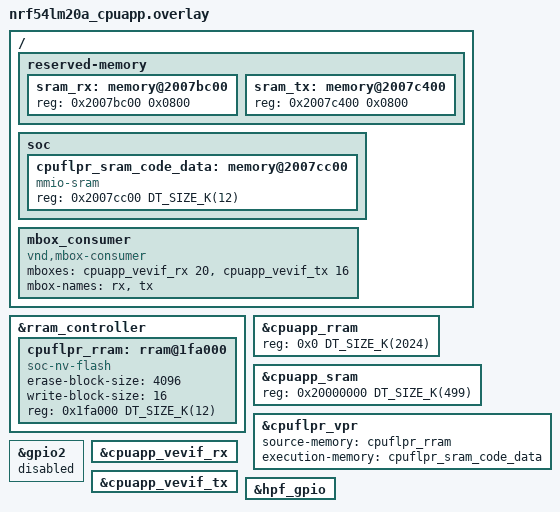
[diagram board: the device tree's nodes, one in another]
/*
 * Copyright (c) 2025 Nordic Semiconductor ASA
 *
 * SPDX-License-Identifier: LicenseRef-Nordic-5-Clause
 */

#include "../../hpf-gpio-app.overlay"

/ {
	reserved-memory {
		#address-cells = <1>;
		#size-cells = <1>;

		sram_rx: memory@2007bc00 {
			reg = <0x2007bc00 0x0800>;
		};

		sram_tx: memory@2007c400 {
			reg = <0x2007c400 0x0800>;
		};
	};

	soc {
		cpuflpr_sram_code_data: memory@2007cc00 {
			compatible = "mmio-sram";
			reg = <0x2007cc00 DT_SIZE_K(12)>;
			#address-cells = <1>;
			#size-cells = <1>;
			ranges = <0x0 0x2007cc00 DT_SIZE_K(12)>;
		};
	};

	mbox_consumer {
		compatible = "vnd,mbox-consumer";
		mboxes = <&cpuapp_vevif_rx 20>, <&cpuapp_vevif_tx 16>;
		mbox-names = "rx", "tx";
	};
};

&rram_controller {
	cpuflpr_rram: rram@1fa000 {
		compatible = "soc-nv-flash";
		erase-block-size = <4096>;
		write-block-size = <16>;
		reg = <0x1fa000 DT_SIZE_K(12)>;
	};
};

&cpuapp_rram {
	reg = <0x0 DT_SIZE_K(2024)>;
};

&cpuapp_sram {
	reg = <0x20000000 DT_SIZE_K(499)>;
	ranges = <0x0 0x20000000 DT_SIZE_K(499)>;
};

&cpuflpr_vpr {
	source-memory = <&cpuflpr_rram>;
	execution-memory = <&cpuflpr_sram_code_data>;
};

&gpio2 {
	status = "disabled";
};

&cpuapp_vevif_rx {
	status = "okay";
};

&cpuapp_vevif_tx {
	status = "okay";
};

&hpf_gpio {
	status = "okay";
};
